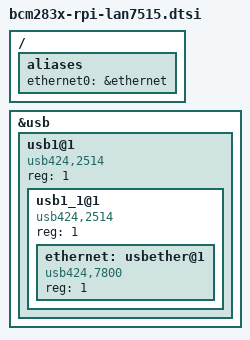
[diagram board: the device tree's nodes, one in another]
// SPDX-License-Identifier: GPL-2.0
/ {
	aliases {
		ethernet0 = &ethernet;
	};
};

&usb {
	usb1@1 {
		compatible = "usb424,2514";
		reg = <1>;
		#address-cells = <1>;
		#size-cells = <0>;

		usb1_1@1 {
			compatible = "usb424,2514";
			reg = <1>;
			#address-cells = <1>;
			#size-cells = <0>;

			ethernet: usbether@1 {
				compatible = "usb424,7800";
				reg = <1>;
			};
		};
	};
};
